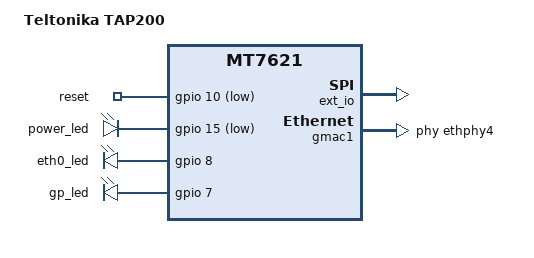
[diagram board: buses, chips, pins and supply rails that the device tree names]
#include "mt7621-teltonika-common.dtsi"
#include "mt7621-teltonika-tap200-flash.dtsi"

/ {
	compatible = "teltonika,tap200", "mediatek,mt7621-soc";
	model = "Teltonika TAP200";

	chosen {
		bootargs = "console=ttyS0,115200 rootfstype=squashfs,jffs2 root=/dev/mtdblock6";
	};

	ext_io {
		compatible = "spi-gpio";
		#address-cells = <1>;
		#size-cells = <0>;
	};

	gpio-export {
		compatible = "gpio-export";
		#size-cells = <0>;

		gpio_reset {
			gpio-export,name = "reset";
			gpios = <&gpio 10 GPIO_ACTIVE_LOW>;
		};
	};

	leds {
		compatible = "gpio-leds";

		power_led {
			label = "power_led";
			default-state = "on";
			gpios = <&gpio 15 GPIO_ACTIVE_LOW>;
		};

		eth0_led {
			label = "eth0_led";
			gpios = <&gpio 8 GPIO_ACTIVE_HIGH>;
		};

		gp_led {
			label = "gp_led";
			gpios = <&gpio 7 GPIO_ACTIVE_HIGH>;
		};
	};

	tlt_gpios { // Modify according to wiki page "DTS syntax with Libgpiod changes"
		gpiochip_info {
			hw_0 {
				hwver = <0>;
				gpiochip_count = <3>;

				gpiochip_0 = <32>; // Built-in
				gpiochip_1 = <32>; // Built-in
				gpiochip_2 = <32>; // Built-in
			};
		};

		misc {
			GPIO_7 {
				line_name = "LED_GP";
			};
		};
	};
};

&state_default {
	gpio {
		groups = "wdt", "jtag", "sdhci", "uart2", "uart3";
		function = "gpio";
	};
};

&gmac1 {
	status = "okay";
	label = "eth1";
	phy-handle = <&ethphy4>;
	nvmem-cells = <&macaddr_config_0 1>;
	nvmem-cell-names = "mac-address";
};

&ethphy4 {
	/delete-property/ interrupts;
};
